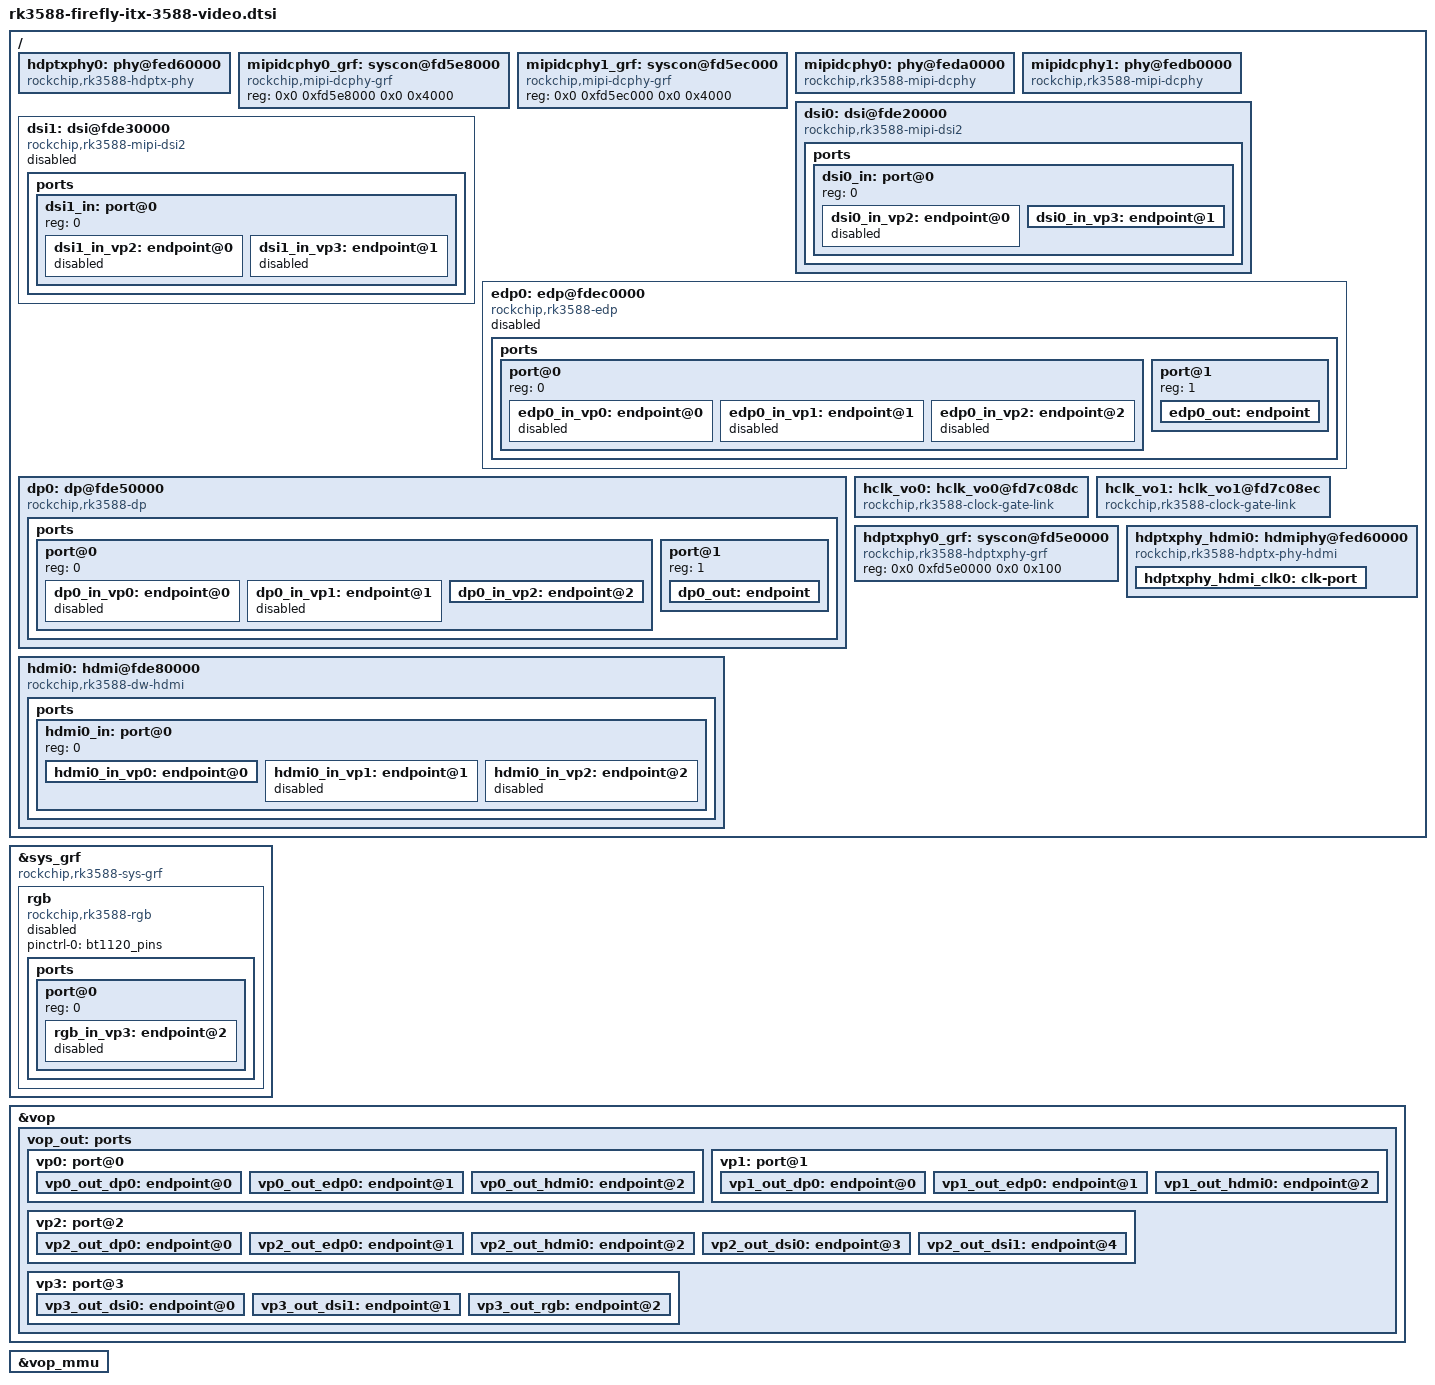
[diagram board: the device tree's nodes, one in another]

#include <dt-bindings/display/rockchip_vop.h>

/ {
    hdptxphy0: phy@fed60000 {
        compatible = "rockchip,rk3588-hdptx-phy";
        reg = <0x0 0xfed60000 0x0 0x2000>;
        clocks = <&cru CLK_USB2PHY_HDPTXRXPHY_REF>, <&cru PCLK_HDPTX0>;
        clock-names = "ref", "apb";
        resets = <&cru SRST_P_HDPTX0>, <&cru SRST_HDPTX0_INIT>,
                 <&cru SRST_HDPTX0_CMN>, <&cru SRST_HDPTX0_LANE>;
        reset-names = "apb", "init", "cmn", "lane";
        rockchip,grf = <&hdptxphy0_grf>;
        #phy-cells = <0>;
        status = "disabled";
    };

    mipidcphy0_grf: syscon@fd5e8000 {
        compatible = "rockchip,mipi-dcphy-grf", "syscon";
        reg = <0x0 0xfd5e8000 0x0 0x4000>;
    };

    mipidcphy1_grf: syscon@fd5ec000 {
        compatible = "rockchip,mipi-dcphy-grf", "syscon";
        reg = <0x0 0xfd5ec000 0x0 0x4000>;
    };

    mipidcphy0: phy@feda0000 {
        compatible = "rockchip,rk3588-mipi-dcphy";
        reg = <0x0 0xfeda0000 0x0 0x10000>;
        rockchip,grf = <&mipidcphy0_grf>;
        clocks = <&cru PCLK_MIPI_DCPHY0>,
                 <&cru CLK_USBDPPHY_MIPIDCPPHY_REF>;
        clock-names = "pclk", "ref";
        resets = <&cru SRST_M_MIPI_DCPHY0>,
                 <&cru SRST_P_MIPI_DCPHY0>,
                 <&cru SRST_P_MIPI_DCPHY0_GRF>,
                 <&cru SRST_S_MIPI_DCPHY0>;
        reset-names = "m_phy", "apb", "grf", "s_phy";
        #phy-cells = <0>;
        status = "okay";
    };

    mipidcphy1: phy@fedb0000 {
        compatible = "rockchip,rk3588-mipi-dcphy";
        reg = <0x0 0xfedb0000 0x0 0x10000>;
        rockchip,grf = <&mipidcphy1_grf>;
        clocks = <&cru PCLK_MIPI_DCPHY1>,
                 <&cru CLK_USBDPPHY_MIPIDCPPHY_REF>;
        clock-names = "pclk", "ref";
        resets = <&cru SRST_M_MIPI_DCPHY1>,
                 <&cru SRST_P_MIPI_DCPHY1>,
                 <&cru SRST_P_MIPI_DCPHY1_GRF>,
                 <&cru SRST_S_MIPI_DCPHY1>;
        reset-names = "m_phy", "apb", "grf", "s_phy";
        #phy-cells = <0>;
        status = "okay";
    };

    dsi0: dsi@fde20000 {
        compatible = "rockchip,rk3588-mipi-dsi2";
        firefly-check;
        reg = <0x0 0xfde20000 0x0 0x10000>;
        interrupts = <GIC_SPI 167 IRQ_TYPE_LEVEL_HIGH 0>;
        clocks = <&cru PCLK_DSIHOST0>, <&cru CLK_DSIHOST0>;
        clock-names = "pclk", "sys_clk";
        resets = <&cru SRST_P_DSIHOST0>;
        reset-names = "apb";
        power-domains = <&power RK3588_PD_VOP>;
        phys = <&mipidcphy0>;
        phy-names = "dcphy";
        rockchip,grf = <&vop_grf>;
        #address-cells = <1>;
        #size-cells = <0>;
        status = "disabled";

        ports {
            #address-cells = <1>;
            #size-cells = <0>;

            dsi0_in: port@0 {
                reg = <0>;
                #address-cells = <1>;
                #size-cells = <0>;

                dsi0_in_vp2: endpoint@0 {
                    reg = <0>;
                    remote-endpoint = <&vp2_out_dsi0>;
                    status = "disabled";
                };

                dsi0_in_vp3: endpoint@1 {
                    reg = <1>;
                    remote-endpoint = <&vp3_out_dsi0>;
                    status = "disabled";
                };
            };
        };
    };

    dsi1: dsi@fde30000 {
        compatible = "rockchip,rk3588-mipi-dsi2";
        reg = <0x0 0xfde30000 0x0 0x10000>;
        interrupts = <GIC_SPI 168 IRQ_TYPE_LEVEL_HIGH 0>;
        clocks = <&cru PCLK_DSIHOST1>, <&cru CLK_DSIHOST1>;
        clock-names = "pclk", "sys_clk";
        resets = <&cru SRST_P_DSIHOST1>;
        reset-names = "apb";
        power-domains = <&power RK3588_PD_VOP>;
        phys = <&mipidcphy1>;
        phy-names = "dcphy";
        rockchip,grf = <&vop_grf>;
        #address-cells = <1>;
        #size-cells = <0>;
        status = "disabled";

        ports {
            #address-cells = <1>;
            #size-cells = <0>;

            dsi1_in: port@0 {
                reg = <0>;
                #address-cells = <1>;
                #size-cells = <0>;

                dsi1_in_vp2: endpoint@0 {
                    reg = <0>;
                    remote-endpoint = <&vp2_out_dsi1>;
                    status = "disabled";
                };

                dsi1_in_vp3: endpoint@1 {
                    reg = <1>;
                    remote-endpoint = <&vp3_out_dsi1>;
                    status = "disabled";
                };
            };
        };
    };

    edp0: edp@fdec0000 {
        compatible = "rockchip,rk3588-edp";
        reg = <0x0 0xfdec0000 0x0 0x1000>;
        interrupts = <GIC_SPI 163 IRQ_TYPE_LEVEL_HIGH 0>;
        clocks = <&cru CLK_EDP0_24M>, <&cru PCLK_EDP0>,
                 <&cru CLK_EDP0_200M>, <&hclk_vo1>;
        clock-names = "dp", "pclk", "spdif", "hclk";
        resets = <&cru SRST_EDP0_24M>, <&cru SRST_P_EDP0>;
        reset-names = "dp", "apb";
        phys = <&hdptxphy0>;
        phy-names = "dp";
        power-domains = <&power RK3588_PD_VO1>;
        rockchip,grf = <&vo1_grf>;
        status = "disabled";

        ports {
            #address-cells = <1>;
            #size-cells = <0>;

            port@0 {
                reg = <0>;
                #address-cells = <1>;
                #size-cells = <0>;

                edp0_in_vp0: endpoint@0 {
                    reg = <0>;
                    remote-endpoint = <&vp0_out_edp0>;
                    status = "disabled";
                };

                edp0_in_vp1: endpoint@1 {
                    reg = <1>;
                    remote-endpoint = <&vp1_out_edp0>;
                    status = "disabled";
                };

                edp0_in_vp2: endpoint@2 {
                    reg = <2>;
                    remote-endpoint = <&vp2_out_edp0>;
                    status = "disabled";
                };
            };

            port@1 {
                reg = <1>;

                edp0_out: endpoint { };
            };
        };
    };

    dp0: dp@fde50000 {
        compatible = "rockchip,rk3588-dp";
        reg = <0x0 0xfde50000 0x0 0x4000>;
        interrupts = <GIC_SPI 161 IRQ_TYPE_LEVEL_HIGH 0>;
        clocks = <&cru PCLK_DP0>, <&cru CLK_AUX16M_0>,
                 <&cru MCLK_I2S4_8CH_TX>, <&cru MCLK_SPDIF2_DP0>,
                 <&hclk_vo0>, <&cru CLK_DP0>;
        clock-names = "apb", "aux", "i2s", "spdif", "hclk", "hdcp";
        assigned-clocks = <&cru CLK_AUX16M_0>;
        assigned-clock-rates = <16000000>;
        resets = <&cru SRST_DP0>;
        phys = <&usbdp_phy0_dp>;
        power-domains = <&power RK3588_PD_VO0>;
        #sound-dai-cells = <1>;
        status = "disabled";

        ports {
            #address-cells = <1>;
            #size-cells = <0>;

            port@0 {
                reg = <0>;
                #address-cells = <1>;
                #size-cells = <0>;

                dp0_in_vp0: endpoint@0 {
                    reg = <0>;
                    remote-endpoint = <&vp0_out_dp0>;
                    status = "disabled";
                };

                dp0_in_vp1: endpoint@1 {
                    reg = <1>;
                    remote-endpoint = <&vp1_out_dp0>;
                    status = "disabled";
                };

                dp0_in_vp2: endpoint@2 {
                    reg = <2>;
                    remote-endpoint = <&vp2_out_dp0>;
                    status = "disabled";
                };
            };

            port@1 {
                reg = <1>;

                dp0_out: endpoint { };
            };
        };
    };

    hclk_vo0: hclk_vo0@fd7c08dc {
        compatible = "rockchip,rk3588-clock-gate-link";
        reg = <0 0xfd7c08dc 0 0x10>;
        clock-names = "link";
        clocks = <&cru HCLK_VOP_ROOT>;
        #power-domain-cells = <1>;
        #clock-cells = <0>;
    };

    hclk_vo1: hclk_vo1@fd7c08ec {
        compatible = "rockchip,rk3588-clock-gate-link";
        reg = <0 0xfd7c08ec 0 0x10>;
        clock-names = "link";
        clocks = <&cru HCLK_VO1USB_TOP_ROOT>;
        #power-domain-cells = <1>;
        #clock-cells = <0>;
    };

    hdptxphy0_grf: syscon@fd5e0000 {
        compatible = "rockchip,rk3588-hdptxphy-grf", "syscon";
        reg = <0x0 0xfd5e0000 0x0 0x100>;
    };

    hdptxphy_hdmi0: hdmiphy@fed60000 {
        compatible = "rockchip,rk3588-hdptx-phy-hdmi";
        reg = <0x0 0xfed60000 0x0 0x2000>;
        clocks = <&cru CLK_USB2PHY_HDPTXRXPHY_REF>, <&cru PCLK_HDPTX0>;
        clock-names = "ref", "apb";
        resets = <&cru SRST_HDPTX0>, <&cru SRST_P_HDPTX0>,
                 <&cru SRST_HDPTX0_INIT>, <&cru SRST_HDPTX0_CMN>,
                 <&cru SRST_HDPTX0_LANE>, <&cru SRST_HDPTX0_ROPLL>,
                 <&cru SRST_HDPTX0_LCPLL>;
        reset-names = "phy", "apb", "init", "cmn", "lane", "ropll",
                      "lcpll";
        rockchip,grf = <&hdptxphy0_grf>;
        #phy-cells = <0>;
        status = "disabled";

        hdptxphy_hdmi_clk0: clk-port {
            #clock-cells = <0>;
            status = "okay";
        };
    };

    hdmi0: hdmi@fde80000 {
        compatible = "rockchip,rk3588-dw-hdmi";
        reg = <0x0 0xfde80000 0x0 0x10000>, <0x0 0xfde90000 0x0 0x10000>;
        interrupts = <GIC_SPI 169 IRQ_TYPE_LEVEL_HIGH 0>,
                     <GIC_SPI 170 IRQ_TYPE_LEVEL_HIGH 0>,
                     <GIC_SPI 171 IRQ_TYPE_LEVEL_HIGH 0>,
                     <GIC_SPI 172 IRQ_TYPE_LEVEL_HIGH 0>,
                     <GIC_SPI 360 IRQ_TYPE_LEVEL_HIGH 0>;
        clocks = <&cru PCLK_HDMITX0>,
                 <&cru CLK_HDMIHDP0>,
                 <&cru CLK_HDMITX0_EARC>,
                 <&cru CLK_HDMITX0_REF>,
                 <&cru MCLK_I2S5_8CH_TX>,
                 <&cru DCLK_VOP0>,
                 <&cru DCLK_VOP1>,
                 <&cru DCLK_VOP2>,
                 <&cru DCLK_VOP3>,
                 <&hclk_vo1>,
                 <&hdptxphy_hdmi_clk0>;
        clock-names = "pclk",
                      "hpd",
                      "earc",
                      "hdmitx_ref",
                      "aud",
                      "dclk_vp0",
                      "dclk_vp1",
                      "dclk_vp2",
                      "dclk_vp3",
                      "hclk_vo1",
                      "link_clk";
        resets = <&cru SRST_HDMITX0_REF>, <&cru SRST_HDMIHDP0>;
        reset-names = "ref", "hdp";
        power-domains = <&power RK3588_PD_VO1>;
        pinctrl-names = "default";
        pinctrl-0 = <&hdmim0_tx0_cec &hdmim0_tx0_hpd &hdmim0_tx0_scl &hdmim0_tx0_sda>;
        reg-io-width = <4>;
        rockchip,grf = <&sys_grf>;
        rockchip,vo1_grf = <&vo1_grf>;
        phys = <&hdptxphy_hdmi0>;
        phy-names = "hdmi";
        #sound-dai-cells = <0>;
        status = "disabled";

        ports {
            #address-cells = <1>;
            #size-cells = <0>;

            hdmi0_in: port@0 {
                reg = <0>;
                #address-cells = <1>;
                #size-cells = <0>;

                hdmi0_in_vp0: endpoint@0 {
                    reg = <0>;
                    remote-endpoint = <&vp0_out_hdmi0>;
                    status = "disabled";
                };

                hdmi0_in_vp1: endpoint@1 {
                    reg = <1>;
                    remote-endpoint = <&vp1_out_hdmi0>;
                    status = "disabled";
                };

                hdmi0_in_vp2: endpoint@2 {
                    reg = <2>;
                    remote-endpoint = <&vp2_out_hdmi0>;
                    status = "disabled";
                };
            };
        };
    };

};

&sys_grf {
    compatible = "rockchip,rk3588-sys-grf", "syscon", "simple-mfd";

    rgb: rgb {
        compatible = "rockchip,rk3588-rgb";
        pinctrl-names = "default";
        pinctrl-0 = <&bt1120_pins>;
        status = "disabled";

        ports {
            #address-cells = <1>;
            #size-cells = <0>;

            port@0 {
                reg = <0>;
                #address-cells = <1>;
                #size-cells = <0>;

                rgb_in_vp3: endpoint@2 {
                    reg = <2>;
                    remote-endpoint = <&vp3_out_rgb>;
                    status = "disabled";
                };
            };
        };
    };
};

&vop {
    status = "okay";

    /*
      clocks:
    minItems: 5
    items:
      - description: Clock for ddr buffer transfer via axi.
      - description: Clock for the ahb bus to R/W the regs.
      - description: Pixel clock for video port 0.
      - description: Pixel clock for video port 1.
      - description: Pixel clock for video port 2.
      - description: Pixel clock for video port 3.
      - description: Peripheral(vop grf/dsi) clock.

  clock-names:
    minItems: 5
    items:
      - const: aclk
      - const: hclk
      - const: dclk_vp0
      - const: dclk_vp1
      - const: dclk_vp2
      - const: dclk_vp3
      - const: pclk_vop*/
    clocks = <&cru ACLK_VOP>,
             <&cru HCLK_VOP>,
             <&cru DCLK_VOP0>,
             <&cru DCLK_VOP1>,
             <&cru DCLK_VOP2>,
             <&cru DCLK_VOP3>,
             <&cru PCLK_VOP_ROOT>,
             <&cru DCLK_VOP0_SRC>,
             <&cru DCLK_VOP1_SRC>,
             <&cru DCLK_VOP2_SRC>;
    clock-names = "aclk",
                  "hclk",
                  "dclk_vp0",
                  "dclk_vp1",
                  "dclk_vp2",
                  "dclk_vp3",
                  "pclk_vop",
                  "dclk_src_vp0",
                  "dclk_src_vp1",
                  "dclk_src_vp2";
    assigned-clocks = <&cru ACLK_VOP>;
    assigned-clock-rates = <750000000>;
    resets = <&cru SRST_A_VOP>,
             <&cru SRST_H_VOP>,
             <&cru SRST_D_VOP0>,
             <&cru SRST_D_VOP1>,
             <&cru SRST_D_VOP2>,
             <&cru SRST_D_VOP3>;
    reset-names = "axi",
                  "ahb",
                  "dclk_vp0",
                  "dclk_vp1",
                  "dclk_vp2",
                  "dclk_vp3";

    /delete-node/ vop_out;

    vop_out: ports {
        #address-cells = <1>;
        #size-cells = <0>;

        vp0: port@0 {
            #address-cells = <1>;
            #size-cells = <0>;
            reg = <0>;

            vp0_out_dp0: endpoint@0 {
                reg = <0>;
                remote-endpoint = <&dp0_in_vp0>;
            };

            vp0_out_edp0: endpoint@1 {
                reg = <1>;
                remote-endpoint = <&edp0_in_vp0>;
            };

            vp0_out_hdmi0: endpoint@2 {
                reg = <2>;
                remote-endpoint = <&hdmi0_in_vp0>;
            };

        };

        vp1: port@1 {
            #address-cells = <1>;
            #size-cells = <0>;
            reg = <1>;

            vp1_out_dp0: endpoint@0 {
                reg = <0>;
                remote-endpoint = <&dp0_in_vp1>;
            };

            vp1_out_edp0: endpoint@1 {
                reg = <1>;
                remote-endpoint = <&edp0_in_vp1>;
            };

            vp1_out_hdmi0: endpoint@2 {
                reg = <2>;
                remote-endpoint = <&hdmi0_in_vp1>;
            };
        };

        vp2: port@2 {
            #address-cells = <1>;
            #size-cells = <0>;
            reg = <2>;

            assigned-clocks = <&cru DCLK_VOP2_SRC>;
            assigned-clock-parents = <&cru PLL_V0PLL>;

            vp2_out_dp0: endpoint@0 {
                reg = <0>;
                remote-endpoint = <&dp0_in_vp2>;
            };

            vp2_out_edp0: endpoint@1 {
                reg = <1>;
                remote-endpoint = <&edp0_in_vp2>;
            };

            vp2_out_hdmi0: endpoint@2 {
                reg = <2>;
                remote-endpoint = <&hdmi0_in_vp2>;
            };

            vp2_out_dsi0: endpoint@3 {
                reg = <3>;
                remote-endpoint = <&dsi0_in_vp2>;
            };

            vp2_out_dsi1: endpoint@4 {
                reg = <4>;
                remote-endpoint = <&dsi1_in_vp2>;
            };
        };

        vp3: port@3 {
            #address-cells = <1>;
            #size-cells = <0>;
            reg = <3>;

            vp3_out_dsi0: endpoint@0 {
                reg = <0>;
                remote-endpoint = <&dsi0_in_vp3>;
            };

            vp3_out_dsi1: endpoint@1 {
                reg = <1>;
                remote-endpoint = <&dsi1_in_vp3>;
            };

            vp3_out_rgb: endpoint@2 {
                reg = <2>;
                remote-endpoint = <&rgb_in_vp3>;
            };
        };
    };
};

/* vp0 & vp1 splice for 8K output */
&vp0 {
    rockchip,plane-mask = <(1 << ROCKCHIP_VOP2_CLUSTER0 | 1 << ROCKCHIP_VOP2_ESMART0)>;
    rockchip,primary-plane = <ROCKCHIP_VOP2_ESMART0>;
    assigned-clocks = <&cru ACLK_VOP>;
    assigned-clock-rates = <800000000>;
};

&vp1 {
    rockchip,plane-mask = <(1 << ROCKCHIP_VOP2_CLUSTER1 | 1 << ROCKCHIP_VOP2_ESMART1)>;
    rockchip,primary-plane = <ROCKCHIP_VOP2_ESMART1>;
};

&vp2 {
    rockchip,plane-mask = <(1 << ROCKCHIP_VOP2_CLUSTER2 | 1 << ROCKCHIP_VOP2_ESMART2)>;
    rockchip,primary-plane = <ROCKCHIP_VOP2_ESMART2>;
};

&vp3 {
    rockchip,plane-mask = <(1 << ROCKCHIP_VOP2_CLUSTER3 | 1 << ROCKCHIP_VOP2_ESMART3)>;
    rockchip,primary-plane = <ROCKCHIP_VOP2_ESMART3>;
};

&dp0 {
    status = "okay";
};

/*
&dp0_in_vp0 {
    status = "okay";
};

&dp0_in_vp1 {
    status = "okay";
};
*/

&dp0_in_vp2 {
    status = "okay";
};

/*

&edp0 {
    status = "okay";
};

&edp0_in_vp0 {
    status = "okay";
};

&edp0_in_vp1 {
    status = "okay";
};

&edp0_in_vp2 {
    status = "okay";
};
*/

&dsi0 {
    status = "okay";
};

/*
&dsi0_in_vp2 {
    status = "okay";
};
*/
&dsi0_in_vp3 {
    status = "okay";
};

/*

&dsi1 {
    status = "okay";
};

&dsi1_in_vp2 {
    status = "okay";
};

&dsi1_in_vp3 {
    status = "okay";
};

&rgb {
    status = "okay";
};

&rgb_in_vp3 {
    status = "okay";
};
*/
&vop_mmu {
    status = "okay";
};

&hdmi0 {
    enable-gpios = <&gpio4 RK_PA0 GPIO_ACTIVE_HIGH>;
    status = "okay";
};

&hdmi0_in_vp0 {
    status = "okay";
};

/*
&hdmi0_in_vp1 {
    status = "okay";
};

&hdmi0_in_vp2 {
    status = "okay";
};
*/

&hdptxphy0 {
    status = "okay";
};

&hdptxphy_hdmi0 {
    status = "okay";
};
